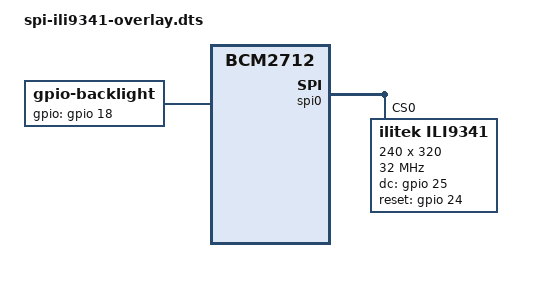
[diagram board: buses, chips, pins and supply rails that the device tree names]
// Raspberry Pi 5 - SPI TFT Display Overlays
// Device Tree Overlays for various SPI displays
// Copyright (C) 2025 The Android Open Source Project

/dts-v1/;
/plugin/;

// ============================================================================
// Generic ILI9341 2.8" TFT Display (240x320)
// ============================================================================
/ {
    compatible = "brcm,bcm2712";
    
    fragment@0 {
        target = <&spi0>;
        __overlay__ {
            status = "okay";
            #address-cells = <1>;
            #size-cells = <0>;
            
            ili9341: ili9341@0 {
                compatible = "ilitek,ili9341";
                reg = <0>;
                spi-max-frequency = <32000000>;
                
                dc-gpios = <&gpio 25 0>;
                reset-gpios = <&gpio 24 0>;
                
                width = <240>;
                height = <320>;
                buswidth = <8>;
                rotate = <270>;
                fps = <30>;
                bgr;
            };
        };
    };
    
    fragment@1 {
        target = <&gpio>;
        __overlay__ {
            ili9341_pins: ili9341_pins {
                brcm,pins = <24 25>;
                brcm,function = <1 1>;  // Output
            };
        };
    };
    
    fragment@2 {
        target-path = "/";
        __overlay__ {
            backlight: backlight {
                compatible = "gpio-backlight";
                gpios = <&gpio 18 0>;
                default-on;
            };
        };
    };
};
